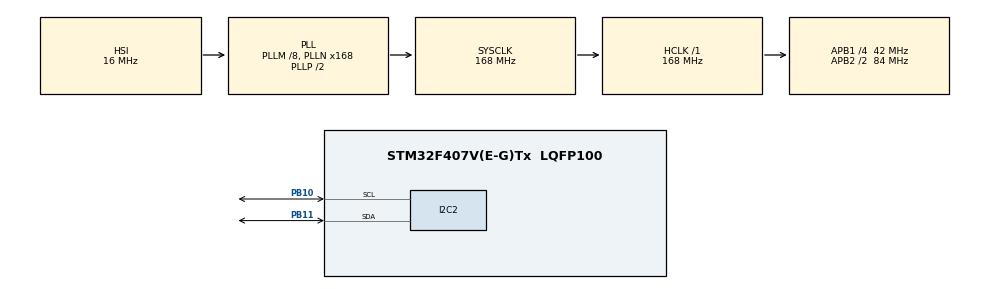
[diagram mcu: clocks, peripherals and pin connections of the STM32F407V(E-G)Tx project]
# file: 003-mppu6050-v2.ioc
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I2C2.I2C_Mode=I2C_Fast
Mcu.Family=STM32F4
Mcu.Name=STM32F407V(E-G)Tx
Mcu.Package=LQFP100
NVIC.PriorityGroup=NVIC_PRIORITYGROUP_4
PB10.Mode=I2C
PB10.Signal=I2C2_SCL
PB11.Mode=I2C
PB11.Signal=I2C2_SDA
PH0-OSC_IN.Mode=HSE-External-Oscillator
PH0-OSC_IN.Signal=RCC_OSC_IN
PH1-OSC_OUT.Mode=HSE-External-Oscillator
PH1-OSC_OUT.Signal=RCC_OSC_OUT
ProjectManager.HeapSize=0x200
ProjectManager.StackSize=0x400
ProjectManager.TargetToolchain=STM32CubeIDE
RCC.48MHZClocksFreq_Value=84000000
RCC.AHBFreq_Value=168000000
RCC.APB1CLKDivider=RCC_HCLK_DIV4
RCC.APB1Freq_Value=42000000
RCC.APB1TimFreq_Value=84000000
RCC.APB2CLKDivider=RCC_HCLK_DIV2
RCC.APB2Freq_Value=84000000
RCC.APB2TimFreq_Value=168000000
RCC.CortexFreq_Value=168000000
RCC.HCLKFreq_Value=168000000
RCC.HSE_VALUE=25000000
RCC.HSI_VALUE=16000000
RCC.LSE_VALUE=32768
RCC.PLLM=8
RCC.PLLN=168
RCC.SYSCLKFreq_VALUE=168000000
RCC.SYSCLKSource=RCC_SYSCLKSOURCE_PLLCLK
RCC.VCOOutputFreq_Value=336000000
board=custom

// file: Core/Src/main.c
/* USER CODE BEGIN Header */
/**
  ******************************************************************************
  * @file           : main.c
  * @brief          : Main program body
  ******************************************************************************
  * @attention
  *mppu6050
  * Copyright (c) 2022 STMicroelectronics.
  * All rights reserved.
  *
  * This software is licensed under terms that can be found in the LICENSE file
  * in the root directory of this software component.
  * If no LICENSE file comes with this software, it is provided AS-IS.
  *
  ******************************************************************************
  */
/* USER CODE END Header */
#include "main.h"

/* USER CODE BEGIN Includes */

#include "mpu6050.h"
#include <math.h>
#include <string.h>
#include <stdio.h>
#include "MadgwickAHRS.h"
double   temperature=0;
char     datax[120];
unsigned long last_read_time;
double         last_x_angle;  // These are the filtered angles
double         last_y_angle;
double         last_z_angle;

void set_last_read_angle_data(unsigned long time, double x, double y, double z) {
  last_read_time = time;
  last_x_angle = x;
  last_y_angle = y;
  last_z_angle = z;
}

inline unsigned long get_last_time() {return last_read_time;}
inline double get_last_x_angle() {return last_x_angle;}
inline double get_last_y_angle() {return last_y_angle;}
inline double get_last_z_angle() {return last_z_angle;}

double    base_x_gyro = 0;
double    base_y_gyro = 0;
double    base_z_gyro = 0;
/* USER CODE END Includes */

 I2C_HandleTypeDef hi2c2;

/* USER CODE BEGIN PV */
 MPU6050_t MPU6050;

/* USER CODE END PV */

void SystemClock_Config(void);
static void MX_GPIO_Init(void);
static void MX_I2C2_Init(void);

/* USER CODE BEGIN 0 */
uint8_t check = 1;
uint8_t data[16];
char str[16];

/* USER CODE END 0 */

int main(void)
{

  /* MCU Configuration--------------------------------------------------------*/

  /* Reset of all peripherals, Initializes the Flash interface and the Systick. */
  HAL_Init();

  /* Configure the system clock */
  SystemClock_Config();

  /* Initialize all configured peripherals */
  MX_GPIO_Init();
  MX_I2C2_Init();
  /* USER CODE BEGIN 2 */
  double angle_x;
  double angle_y;
  /* USER CODE END 2 */

  /* Infinite loop */
  /* USER CODE BEGIN WHILE */
  check = MPU6050_Init(&hi2c2);

    itoa(check, str, 10);
    //set_last_read_angle_data(1, 0, 0, 0);
  while (1)
  {//mppu6050
    /* USER CODE END WHILE */
	  MPU6050_Read_All(&hi2c2, &MPU6050);
	 //	  angle_x = MPU6050.KalmanAngleX;
	 //	  angle_y = MPU6050.KalmanAngleY;

	 	  //double angle_z = MPU6050.Az;
	 	  double accel_x_raw = MPU6050.Ax;
	 	  double accel_y_raw = MPU6050.Ay;
	 	  double accel_z_raw = MPU6050.Az;

	 	  double gyro_x_raw = MPU6050.Gx;
	 	  double gyro_y_raw = MPU6050.Gy;
	 	  double gyro_z_raw = MPU6050.Gz;
	 	 MadgwickAHRSupdateIMU(gyro_x_raw, gyro_y_raw, gyro_z_raw, accel_x_raw, accel_y_raw, accel_z_raw);

  }
}

void SystemClock_Config(void)
{
  RCC_OscInitTypeDef RCC_OscInitStruct = {0};
  RCC_ClkInitTypeDef RCC_ClkInitStruct = {0};

  /** Configure the main internal regulator output voltage
  */
  __HAL_RCC_PWR_CLK_ENABLE();
  __HAL_PWR_VOLTAGESCALING_CONFIG(PWR_REGULATOR_VOLTAGE_SCALE1);

  /** Initializes the RCC Oscillators according to the specified parameters
  * in the RCC_OscInitTypeDef structure.
  */
  RCC_OscInitStruct.OscillatorType = RCC_OSCILLATORTYPE_HSI;
  RCC_OscInitStruct.HSIState = RCC_HSI_ON;
  RCC_OscInitStruct.HSICalibrationValue = RCC_HSICALIBRATION_DEFAULT;
  RCC_OscInitStruct.PLL.PLLState = RCC_PLL_ON;
  RCC_OscInitStruct.PLL.PLLSource = RCC_PLLSOURCE_HSI;
  RCC_OscInitStruct.PLL.PLLM = 8;
  RCC_OscInitStruct.PLL.PLLN = 168;
  RCC_OscInitStruct.PLL.PLLP = RCC_PLLP_DIV2;
  RCC_OscInitStruct.PLL.PLLQ = 4;
  if (HAL_RCC_OscConfig(&RCC_OscInitStruct) != HAL_OK)
  {
    Error_Handler();
  }

  /** Initializes the CPU, AHB and APB buses clocks
  */
  RCC_ClkInitStruct.ClockType = RCC_CLOCKTYPE_HCLK|RCC_CLOCKTYPE_SYSCLK
                              |RCC_CLOCKTYPE_PCLK1|RCC_CLOCKTYPE_PCLK2;
  RCC_ClkInitStruct.SYSCLKSource = RCC_SYSCLKSOURCE_PLLCLK;
  RCC_ClkInitStruct.AHBCLKDivider = RCC_SYSCLK_DIV1;
  RCC_ClkInitStruct.APB1CLKDivider = RCC_HCLK_DIV4;
  RCC_ClkInitStruct.APB2CLKDivider = RCC_HCLK_DIV2;

  if (HAL_RCC_ClockConfig(&RCC_ClkInitStruct, FLASH_LATENCY_5) != HAL_OK)
  {
    Error_Handler();
  }
}

static void MX_I2C2_Init(void)
{

  hi2c2.Instance = I2C2;
  hi2c2.Init.ClockSpeed = 400000;
  hi2c2.Init.DutyCycle = I2C_DUTYCYCLE_2;
  hi2c2.Init.OwnAddress1 = 0;
  hi2c2.Init.AddressingMode = I2C_ADDRESSINGMODE_7BIT;
  hi2c2.Init.DualAddressMode = I2C_DUALADDRESS_DISABLE;
  hi2c2.Init.OwnAddress2 = 0;
  hi2c2.Init.GeneralCallMode = I2C_GENERALCALL_DISABLE;
  hi2c2.Init.NoStretchMode = I2C_NOSTRETCH_DISABLE;
  if (HAL_I2C_Init(&hi2c2) != HAL_OK)
  {
    Error_Handler();
  }

}

static void MX_GPIO_Init(void)
{

  /* GPIO Ports Clock Enable */
  __HAL_RCC_GPIOH_CLK_ENABLE();
  __HAL_RCC_GPIOB_CLK_ENABLE();

}

void Error_Handler(void)
{
  __disable_irq();
  while (1)
  {
  }
}
